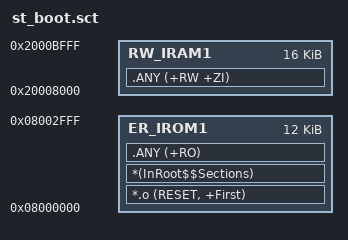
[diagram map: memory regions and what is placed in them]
; *************************************************************
; *** Scatter-Loading Description File generated by uVision ***
; *************************************************************

; Boot image is 12KB and must stay inside the 16KB boot partition.
; Update info is 0x0805F000, not the old page at 0x08003000.
LR_IROM1 0x08000000 0x00003000  {    ; load region size_region
  ER_IROM1 0x08000000 0x00003000  {  ; load address = execution address
   *.o (RESET, +First)
   *(InRoot$$Sections)
   .ANY (+RO)
  }
  RW_IRAM1 0x20008000 0x00004000  {  ; RW data
   .ANY (+RW +ZI)
  }
}

